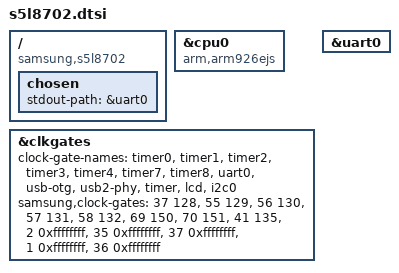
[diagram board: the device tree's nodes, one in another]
// SPDX-License-Identifier: GPL-2.0+ OR MIT
/*
 * Samsung S5L8702 SoC
 *
 * Other names: M1A
 *
 * Copyright (C) 2026 The freemyipod team (freemyipod.org)
 */

#include "s5l87xx.dtsi"
#include "s5l8702-common.dtsi"

/ {
	compatible = "samsung,s5l8702", "apple,arm-platform";

	chosen {
		stdout-path = &uart0;
	};
};

&cpu0 {
	compatible = "arm,arm926ejs";
};

&clkgates {
	/*
	 * Clock-gate name -> {gate, bit} table consumed by s5l87xx_enable_clkgate().
	 * Each entry is two cells: gate * 32 + bit, with 0xffffffff for an unused
	 * second gate. Timers carry a secondary gate 4 enable; S5L8702 itself gates
	 * all timers behind one gate (rockbox CLOCKGATE_TIMER 37 = {1,5}).
	 */
	clock-gate-names = "timer0", "timer1", "timer2", "timer3", "timer4",
					   "timer7", "timer8", "uart0",
					   "usb-otg", "usb2-phy",
					   "timer", "lcd", "i2c0";
	samsung,clock-gates = <37 128>, <55 129>, <56 130>, <57 131>, <58 132>,
						  <69 150>, <70 151>, <41 135>,
						  <2 0xffffffff>, <35 0xffffffff>,
						  <37 0xffffffff>, <1 0xffffffff>, <36 0xffffffff>;
};

&uart0 {
	status = "okay";
};
